AUTOSAR XML (schema 4-3-0)
package /CollisionDetectionApplicationLayer/ApplicationPackage
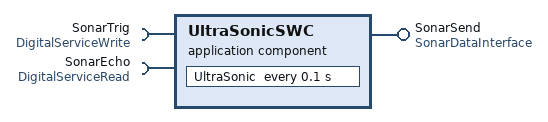
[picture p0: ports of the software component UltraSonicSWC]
  application sw component type UltraSonicSWC
    require port SonarTrig: required-interface=DigitalServiceWrite
    require port SonarEcho: required-interface=DigitalServiceRead
    provide port SonarSend: provided-interface=SonarDataInterface
    behavior UltraSonicSWCBehaviour: data-type-mapping=TypeMappings, handle-termination-and-restart=NO-SUPPORT
      timing event UltraSonic_timingEvent_0_1: start-on-event=UltraSonic, period=0.1
      runnable UltraSonic
        data-write-access:
          access dataWriteAccess_UltraSonic_SonarSend_distance: accessed-variable=SonarSend.distance
        sync call SonarCallTrig: operation=SonarTrig.Write, timeout=0.0
        sync call SonarCallEcho: operation=SonarEcho.Read, timeout=0.0
  swc implementation UltraSonicSWCImpl: programming-language=C, vendor-id=0, behavior=UltraSonicSWCBehaviour
    code-descriptors:
      code src: artifact-descriptors=autosar-engineering-object={short-label=artifactDescriptor, category=artifactDescriptorCategory}
    resource consumption resourceConsumption
